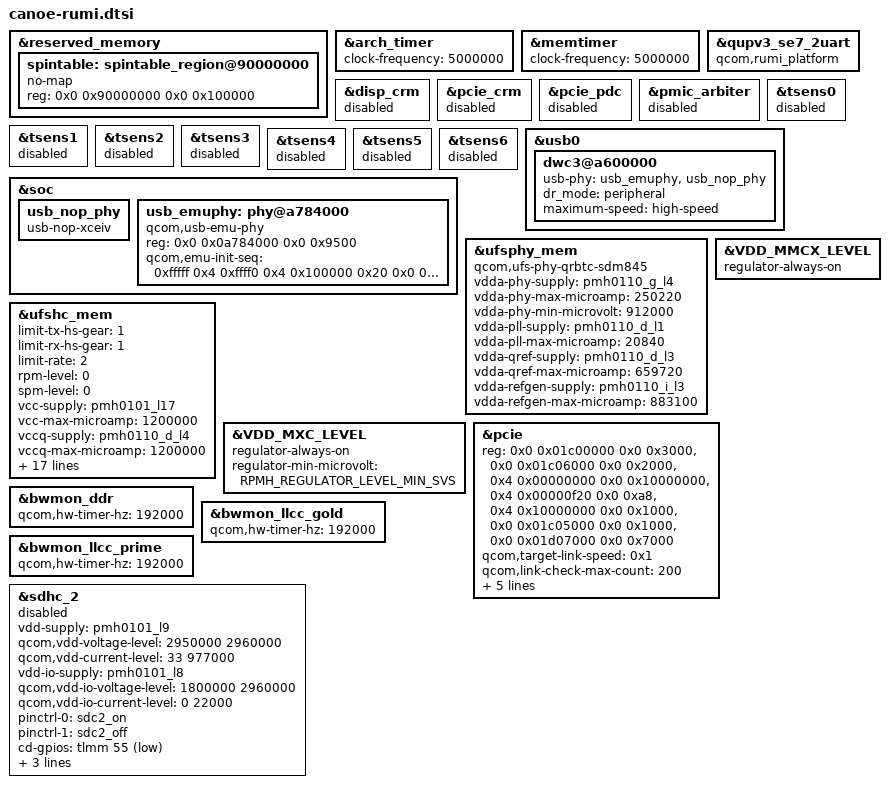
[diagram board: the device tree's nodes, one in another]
// SPDX-License-Identifier: BSD-3-Clause
/*
 * Copyright (c) 2024 Qualcomm Innovation Center, Inc. All rights reserved.
 */
#include <dt-bindings/gpio/gpio.h>
#include <dt-bindings/clock/qcom,gcc-canoe.h>
#include <dt-bindings/clock/qcom,rpmh.h>
#include <dt-bindings/regulator/qcom,rpmh-regulator-levels.h>

#include "canoe-pmic-overlay.dtsi"

&reserved_memory {
	spintable: spintable_region@90000000 {
		no-map;
		reg = <0x0 0x90000000 0x0 0x100000>;
	};
};

&arch_timer {
	clock-frequency = <5000000>;
};

&memtimer {
	clock-frequency = <5000000>;
};

&qupv3_se7_2uart {
	qcom,rumi_platform;
};

&disp_crm {
	status = "disabled";
};

&pcie_crm {
	status = "disabled";
};

&pcie_pdc {
	status = "disabled";
};

&pmic_arbiter {
	status = "disabled";
};

&tsens0 {
	status = "disabled";
};

&tsens1 {
	status = "disabled";
};

&tsens2 {
	status = "disabled";
};

&tsens3 {
	status = "disabled";
};

&tsens4 {
	status = "disabled";
};

&tsens5 {
	status = "disabled";
};

&tsens6 {
	status = "disabled";
};

&soc {
	usb_nop_phy: usb_nop_phy {
		compatible = "usb-nop-xceiv";
	};

	usb_emuphy: phy@a784000 {
		compatible = "qcom,usb-emu-phy";
		reg = <0x0 0x0a784000 0x0 0x9500>;

		qcom,emu-init-seq = <0xfffff 0x4
			0xffff0 0x4
			0x100000 0x20
			0x0 0x20
			0x000101F0 0x20
			0x00100000 0x3c
			0x0 0x3c
			0x0 0x4>;
	};
};

&usb0 {
	dwc3@a600000 {
		usb-phy = <&usb_emuphy>, <&usb_nop_phy>;
		dr_mode = "peripheral";
		maximum-speed = "high-speed";
	};
};

&ufsphy_mem {
	compatible = "qcom,ufs-phy-qrbtc-sdm845";

	/* VDDA_UFS_CORE */
	vdda-phy-supply = <&pmh0110_g_l4>;
	vdda-phy-max-microamp = <250220>;
	/*
	 * Platforms supporting Gear 5 && Rate B require a different
	 * voltage supply. Check the Power Grid document.
	 */
	vdda-phy-min-microvolt = <912000>;

	/* VDDA_UFS_0_1P2 */
	vdda-pll-supply = <&pmh0110_d_l1>;
	vdda-pll-max-microamp = <20840>;

	/* Qref power supply, Refer Qref diagram */
	vdda-qref-supply = <&pmh0110_d_l3>;
	vdda-qref-max-microamp = <659720>;

	/*
	 * Refer to Canoe's Power Grid Analysis document.
	 * Add vote for REFGEN_VDD_A_0P9/VDD_A_PCIE_0_0P9 regulator.
	 */
	vdda-refgen-supply = <&pmh0110_i_l3>;
	vdda-refgen-max-microamp = <883100>;

	status = "ok";
};

&ufshc_mem {
	limit-tx-hs-gear = <1>;
	limit-rx-hs-gear = <1>;
	limit-rate = <2>; /* HS Rate-B */
	rpm-level = <0>;
	spm-level = <0>;

	vcc-supply = <&pmh0101_l17>;
	vcc-max-microamp = <1200000>;

	vccq-supply = <&pmh0110_d_l4>;
	vccq-max-microamp = <1200000>;

	/* UFS Rst pin is always on. It is shared with VDD_PX14 */
	qcom,vddp-ref-clk-supply = <&pmh0110_g_l1>;
	qcom,vddp-ref-clk-max-microamp = <100>;

	qcom,vccq-parent-supply = <&pmh0110_f_s7>;
	qcom,vccq-parent-max-microamp = <8176000>;

	reset-gpios = <&tlmm 217 GPIO_ACTIVE_LOW>;

	resets = <&gcc GCC_UFS_PHY_BCR>;
	reset-names = "rst";


	clock-names =
		"core_clk",
		"bus_aggr_clk",
		"iface_clk",
		"core_clk_unipro",
		"core_clk_ice",
		"ref_clk",
		"tx_lane0_sync_clk",
		"rx_lane0_sync_clk",
		"rx_lane1_sync_clk";
	clocks =
		<&gcc GCC_UFS_PHY_AXI_CLK>,
		<&gcc GCC_AGGRE_UFS_PHY_AXI_CLK>,
		<&gcc GCC_UFS_PHY_AHB_CLK>,
		<&gcc GCC_UFS_PHY_UNIPRO_CORE_CLK>,
		<&gcc GCC_UFS_PHY_ICE_CORE_CLK>,
		<&rpmhcc RPMH_CXO_CLK>,
		<&gcc GCC_UFS_PHY_TX_SYMBOL_0_CLK>,
		<&gcc GCC_UFS_PHY_RX_SYMBOL_0_CLK>,
		<&gcc GCC_UFS_PHY_RX_SYMBOL_1_CLK>;

	qcom,disable-lpm;
	qcom,iommu-dma = "bypass";

	status = "ok";
};

&VDD_MMCX_LEVEL {
	regulator-always-on;
};

&VDD_MXC_LEVEL {
	regulator-always-on;
	regulator-min-microvolt = <RPMH_REGULATOR_LEVEL_MIN_SVS>;
};

&pcie {
	reg = <0x0 0x01c00000 0x0 0x3000>,
		<0x0 0x01c06000 0x0 0x2000>,
		<0x4 0x00000000 0x0 0x10000000>,
		<0x4 0x00000f20 0x0 0xa8>,
		<0x4 0x10000000 0x0 0x1000>,
		<0x0 0x01c05000 0x0 0x1000>,
		<0x0 0x01d07000 0x0 0x7000>;
	reg-names = "parf", "phy", "dm_core", "elbi", "iatu", "rumi", "pcie_sm";
	qcom,target-link-speed = <0x1>;
	qcom,link-check-max-count = <200>; /* 1 sec */
	qcom,no-l0s-supported;
	qcom,no-l1-supported;
	qcom,no-l1ss-supported;
	qcom,no-aux-clk-sync;

	power-domains = <&gcc GCC_PCIE_0_GDSC>;
	power-domain-names = "gdsc-core-vdd";
};

&bwmon_ddr {
	qcom,hw-timer-hz = <192000>;
};

&bwmon_llcc_gold {
	qcom,hw-timer-hz = <192000>;
};

&bwmon_llcc_prime {
	qcom,hw-timer-hz = <192000>;
};

&sdhc_2 {
	vdd-supply = <&pmh0101_l9>;
	qcom,vdd-voltage-level = <2950000 2960000>;
	qcom,vdd-current-level = <33 977000>;

	vdd-io-supply = <&pmh0101_l8>;
	qcom,vdd-io-voltage-level = <1800000 2960000>;
	qcom,vdd-io-current-level = <0 22000>;

	pinctrl-names = "default", "sleep";
	pinctrl-0 = <&sdc2_on>;
	pinctrl-1 = <&sdc2_off>;

	cd-gpios = <&tlmm 55 GPIO_ACTIVE_LOW>;

	resets = <&gcc GCC_SDCC2_BCR>;
	reset-names = "core_reset";

	qcom,iommu-dma = "bypass";
	is_rumi;

	status = "disabled";
};
